VERSION ""

NS_ :

BS_:

BU_:

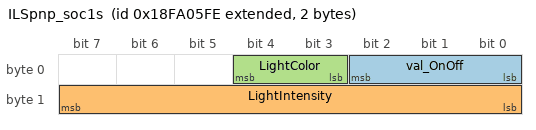
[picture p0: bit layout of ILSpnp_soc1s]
BO_ 2566522366 ILSpnp_soc1s: 2 Vector__XXX
 SG_ val_OnOff : 0|3@1+ (1,0) [0|7] "" Vector__XXX
 SG_ LightIntensity : 8|8@1+ (1,0) [0|0] "%" Vector__XXX
 SG_ LightColor : 3|2@1+ (1,0) [0|3] "" Vector__XXX

CM_ " the Cargo Lighting Request message.
 
$DBC storage: https://item.arrival.co/ui/repos/tree/General/dbc/  $
$Change: change_number $
$DateTime: YYYY/MM/DD HH:MM:SS $
$Revision: #revision_number $
$Author: zuev@arrival.com $";
CM_ SG_ 2566522366 val_OnOff "Indicates the actual state of the cargo light.";
BA_DEF_ SG_  "SigType" ENUM  "Default","Range","RangeSigned","ASCII","Discrete","Control","ReferencePGN","DTC","StringDelimiter","StringLength","StringLengthControl";
BA_DEF_ SG_  "GenSigEVName" STRING ;
BA_DEF_ SG_  "GenSigILSupport" ENUM  "No","Yes";
BA_DEF_ SG_  "GenSigSendType" ENUM  "Cyclic","OnWrite","OnWriteWithRepetition","OnChange","OnChangeWithRepetition","IfActive","IfActiveWithRepetition","NoSigSendType";
BA_DEF_ SG_  "GenSigStartValue" INT 0 2147483647;
BA_DEF_ BO_  "GenMsgDelayTime" INT 0 1000;
BA_DEF_ BO_  "GenMsgILSupport" ENUM  "No","Yes";
BA_DEF_ BU_  "NmStationAddress" INT 0 255;
BA_DEF_ BO_  "GenMsgSendType" ENUM  "cyclic","NotUsed","IfActive","NotUsed","NotUsed","NotUsed","NotUsed","NotUsed","noMsgSendType";
BA_DEF_ BO_  "GenMsgRequestable" INT 0 1;
BA_DEF_ BO_  "GenMsgCycleTime" INT 0 3600000;
BA_DEF_ BO_  "SendOnChange" ENUM  "No","Yes";
BA_DEF_  "DBName" STRING ;
BA_DEF_  "BusType" STRING ;
BA_DEF_  "ProtocolType" STRING ;
BA_DEF_ BO_  "VFrameFormat" ENUM  "StandardCAN","ExtendedCAN","reserved","J1939PG";
BA_DEF_DEF_  "SigType" "Default";
BA_DEF_DEF_  "GenSigEVName" "Env@Nodename_@Signame";
BA_DEF_DEF_  "GenSigILSupport" "Yes";
BA_DEF_DEF_  "GenSigSendType" "NoSigSendType";
BA_DEF_DEF_  "GenSigStartValue" 0;
BA_DEF_DEF_  "GenMsgDelayTime" 0;
BA_DEF_DEF_  "GenMsgILSupport" "Yes";
BA_DEF_DEF_  "NmStationAddress" 254;
BA_DEF_DEF_  "GenMsgSendType" "noMsgSendType";
BA_DEF_DEF_  "GenMsgRequestable" 1;
BA_DEF_DEF_  "GenMsgCycleTime" 0;
BA_DEF_DEF_  "SendOnChange" "No";
BA_DEF_DEF_  "DBName" "";
BA_DEF_DEF_  "BusType" "CAN";
BA_DEF_DEF_  "ProtocolType" "J1939";
BA_DEF_DEF_  "VFrameFormat" "J1939PG";
BA_ "DBName" "ILS_pnp";
BA_ "GenMsgSendType" BO_ 2566522366 0;
BA_ "GenMsgCycleTime" BO_ 2566522366 1000;
BA_ "GenMsgDelayTime" BO_ 2566522366 100;
BA_ "SendOnChange" BO_ 2566522366 1;
BA_ "GenSigStartValue" SG_ 2566522366 val_OnOff 3;
BA_ "GenSigStartValue" SG_ 2566522366 LightColor 3;
VAL_ 2566522366 val_OnOff 3 "Not Available" 2 "Error" 1 "On" 0 "Off" ;
VAL_ 2566522366 LightColor 3 "NA" 2 "Reserved" 1 "WarmWhite" 0 "ColdWhite" ;
